VERSION ""

NS_ :

BS_:

BU_: ODRIVE MOTOR GEO

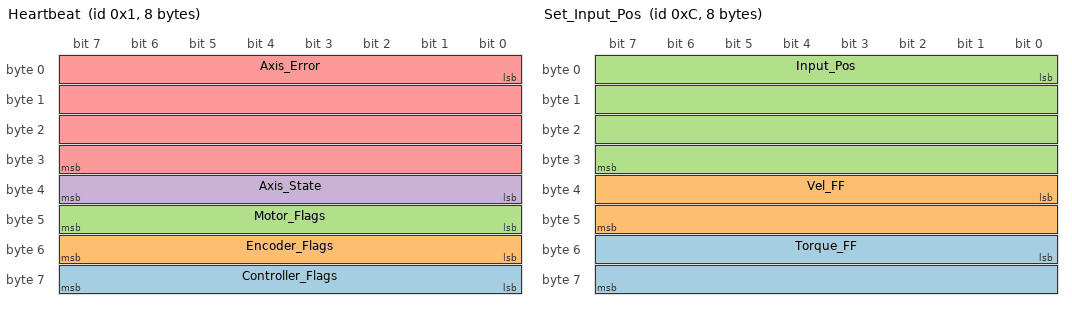
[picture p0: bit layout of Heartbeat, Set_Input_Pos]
BO_ 1 Heartbeat: 8 MOTOR
 SG_ Controller_Flags : 56|8@1+ (1,0) [0|0] "" ODRIVE, MOTOR
 SG_ Encoder_Flags : 48|8@1+ (1,0) [0|0] "" ODRIVE, MOTOR
 SG_ Motor_Flags : 40|8@1+ (1,0) [0|0] "" ODRIVE, MOTOR
 SG_ Axis_State : 32|8@1+ (1,0) [0|0] "" ODRIVE, MOTOR
 SG_ Axis_Error : 0|32@1+ (1,0) [0|0] "" ODRIVE, MOTOR

BO_ 2 Estop: 0 MOTOR

BO_ 3 Get_Motor_Error: 8 MOTOR
 SG_ Motor_Error : 0|32@1+ (1,0) [0|0] "" ODRIVE

BO_ 4 Get_Encoder_Error: 8 MOTOR
 SG_ Encoder_Error : 0|32@1+ (1,0) [0|0] "" ODRIVE

BO_ 5 Get_Sensorless_Error: 8 MOTOR
 SG_ Sensorless_Error : 0|32@1+ (1,0) [0|0] "" ODRIVE

BO_ 6 Set_Axis_Node_ID: 8 MOTOR
 SG_ Axis_Node_ID : 0|32@1+ (1,0) [0|0] "" ODRIVE

BO_ 7 Set_Axis_State: 8 MOTOR
 SG_ Axis_Requested_State : 0|32@1+ (1,0) [0|0] "" ODRIVE

BO_ 9 Get_Encoder_Estimates: 8 MOTOR
 SG_ Vel_Estimate : 32|32@1+ (1,0) [0|0] "" ODRIVE
 SG_ Pos_Estimate : 0|32@1+ (1,0) [0|0] "" ODRIVE

BO_ 10 Get_Encoder_Count: 8 MOTOR
 SG_ Count_in_CPR : 32|32@1+ (1,0) [0|0] "" ODRIVE
 SG_ Shadow_Count : 0|32@1+ (1,0) [0|0] "" ODRIVE

BO_ 11 Set_Controller_Mode: 8 MOTOR
 SG_ Input_Mode : 32|32@1+ (1,0) [0|0] "" ODRIVE
 SG_ Control_Mode : 0|32@1+ (1,0) [0|0] "" ODRIVE

BO_ 12 Set_Input_Pos: 8 MOTOR
 SG_ Torque_FF : 48|16@1- (0.001,0) [0|0] "" ODRIVE
 SG_ Vel_FF : 32|16@1- (0.001,0) [0|0] "" ODRIVE
 SG_ Input_Pos : 0|32@1+ (1,0) [0|0] "" ODRIVE

BO_ 13 Set_Input_Vel: 8 MOTOR
 SG_ Input_Torque_FF : 32|32@1+ (1.0,0) [0|0] "" ODRIVE
 SG_ Input_Vel : 0|32@1+ (1.0,0) [0|0] "" ODRIVE

BO_ 14 Set_Input_Torque: 8 MOTOR
 SG_ Input_Torque : 0|32@1+ (1,0) [0|0] "" ODRIVE

BO_ 15 Set_Limits: 8 MOTOR
 SG_ Current_Limit : 32|32@1+ (1,0) [0|0] "" ODRIVE
 SG_ Velocity_Limit : 0|32@1+ (1,0) [0|0] "" ODRIVE

BO_ 16 Start_Anticogging: 0 MOTOR

BO_ 17 Set_Traj_Vel_Limit: 8 MOTOR
 SG_ Traj_Vel_Limit : 0|32@1+ (1,0) [0|0] "" ODRIVE

BO_ 18 Set_Traj_Accel_Limits: 8 MOTOR
 SG_ Traj_Decel_Limit : 32|32@1+ (1,0) [0|0] "" ODRIVE
 SG_ Traj_Accel_Limit : 0|32@1+ (1,0) [0|0] "" ODRIVE

BO_ 19 Set_Traj_Inertia: 8 MOTOR
 SG_ Traj_Inertia : 0|32@1+ (1,0) [0|0] "" ODRIVE

BO_ 20 Get_Iq: 8 MOTOR
 SG_ Iq_Measured : 32|32@1+ (1,0) [0|0] "" ODRIVE
 SG_ Iq_Setpoint : 0|32@1+ (1,0) [0|0] "" ODRIVE

BO_ 21 Get_Sensorless_Estimates: 8 MOTOR
 SG_ Sensorless_Vel_Estimate : 32|32@1+ (1,0) [0|0] "" ODRIVE
 SG_ Sensorless_Pos_Estimate : 0|32@1+ (1,0) [0|0] "" ODRIVE

BO_ 22 Reboot: 0 MOTOR

BO_ 23 Get_Vbus_Voltage: 8 MOTOR
 SG_ Vbus_Voltage : 0|32@1+ (1,0) [0|0] "" ODRIVE

BO_ 24 Clear_Errors: 0 MOTOR

BO_ 25 Set_Linear_Count: 8 MOTOR
 SG_ Position : 0|32@1- (1,0) [0|0] "" ODRIVE

BO_ 26 Set_Pos_Gain: 8 MOTOR
 SG_ Pos_Gain : 0|32@1+ (1,0) [0|0] "" ODRIVE

BO_ 27 Set_Vel_gains: 8 MOTOR
 SG_ Vel_Integrator_Gain : 32|32@1+ (1,0) [0|0] "" ODRIVE
 SG_ Vel_Gain : 0|32@1+ (1,0) [0|0] "" ODRIVE

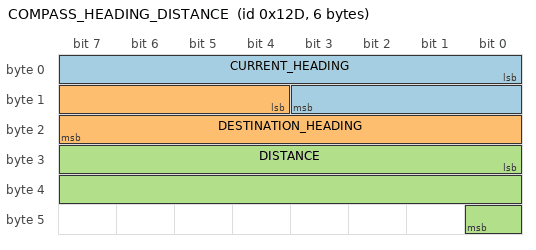
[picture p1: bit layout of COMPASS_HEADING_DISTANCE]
BO_ 301 COMPASS_HEADING_DISTANCE: 6 GEO
 SG_ CURRENT_HEADING : 0|12@1+ (0.1,0) [0|359.9] "Degrees" MOTOR
 SG_ DESTINATION_HEADING: 12|12@1+ (0.1,0) [0|359.9] "Degrees" MOTOR
 SG_ DISTANCE : 24|17@1+ (0.01,0) [0|0] "Meters" MOTOR

BO_ 501 GPS_CURRENT_INFO: 8 GEO
 SG_ GPS_CURRENT_LAT : 0|32@1+ (0.000001,-90.000000) [-90|90] "degrees" MOTOR
 SG_ GPS_CURRENT_LONG : 32|32@1+ (0.000001,-180.000000) [-180|180] "degrees" MOTOR

BO_ 775 DBG_GPS_COMPASS_LOCK_LED_CHECK: 1 GEO
 SG_ COMPASS_LED_STATUS: 0|1@1+ (1,0) [0|0] "TRUE_FALSE" MOTOR
 SG_ GPS_LED_STATUS : 1|1@1+ (1,0) [0|0] "TRUE_FALSE" MOTOR

SIG_VALTYPE_ 9 Pos_Estimate : 1;
SIG_VALTYPE_ 9 Vel_Estimate : 1;
SIG_VALTYPE_ 12 Input_Pos : 1;
SIG_VALTYPE_ 13 Input_Vel : 1;
SIG_VALTYPE_ 13 Input_Torque_FF : 1;
SIG_VALTYPE_ 14 Input_Torque : 1;
SIG_VALTYPE_ 15 Velocity_Limit : 1;
SIG_VALTYPE_ 15 Current_Limit : 1;
SIG_VALTYPE_ 17 Traj_Vel_Limit : 1;
SIG_VALTYPE_ 18 Traj_Accel_Limit : 1;
SIG_VALTYPE_ 18 Traj_Decel_Limit : 1;
SIG_VALTYPE_ 19 Traj_Inertia : 1;
SIG_VALTYPE_ 20 Iq_Setpoint : 1;
SIG_VALTYPE_ 20 Iq_Measured : 1;
SIG_VALTYPE_ 21 Sensorless_Pos_Estimate : 1;
SIG_VALTYPE_ 21 Sensorless_Vel_Estimate : 1;
SIG_VALTYPE_ 23 Vbus_Voltage : 1;
SIG_VALTYPE_ 26 Pos_Gain : 1;
SIG_VALTYPE_ 27 Vel_Gain : 1;
SIG_VALTYPE_ 27 Vel_Integrator_Gain : 1;
